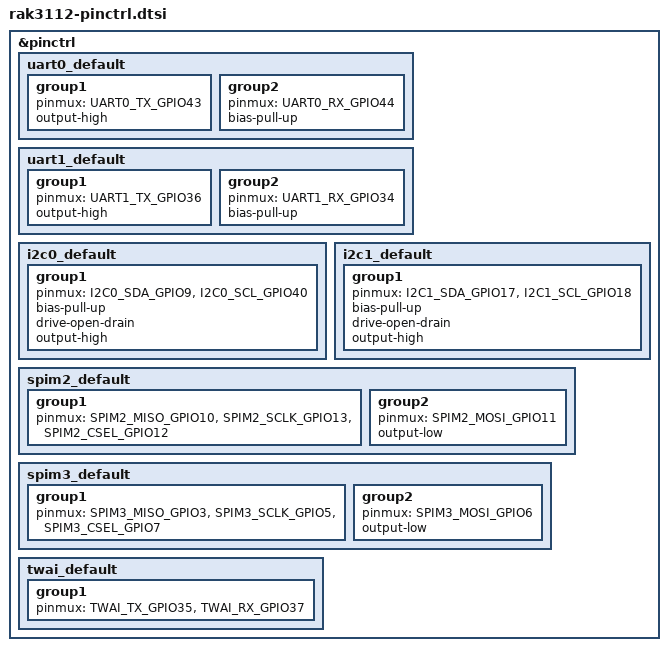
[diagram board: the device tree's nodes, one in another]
/*
 * Copyright (c) 2025 RAKwireless Technology Co., Ltd. <www.rakwireless.com>
 * Sercan Erat <sercanerat@gmail.com>
 * SPDX-License-Identifier: Apache-2.0
 */

/* Do not assign GPIO19 and GPIO20 to any peripheral.
 * These are USB pins.
 */

#include <dt-bindings/pinctrl/esp32s3-pinctrl.h>
#include <zephyr/dt-bindings/pinctrl/esp-pinctrl-common.h>
#include <zephyr/dt-bindings/pinctrl/esp32s3-gpio-sigmap.h>

&pinctrl {
	uart0_default: uart0_default {
		group1 {
			pinmux = <UART0_TX_GPIO43>;
			output-high;
		};
		group2 {
			pinmux = <UART0_RX_GPIO44>;
			bias-pull-up;
		};
	};

	uart1_default: uart1_default {
		/* Not available in the 8MB and 16MB PSRAM version */
		group1 {
			pinmux = <UART1_TX_GPIO36>;
			output-high;
		};
		group2 {
			pinmux = <UART1_RX_GPIO34>;
			bias-pull-up;
		};
	};

	i2c0_default: i2c0_default {
		group1 {
			pinmux = <I2C0_SDA_GPIO9>,
				 <I2C0_SCL_GPIO40>;
			bias-pull-up;
			drive-open-drain;
			output-high;
		};
	};

	i2c1_default: i2c1_default {
		group1 {
			pinmux = <I2C1_SDA_GPIO17>,
				 <I2C1_SCL_GPIO18>;
			bias-pull-up;
			drive-open-drain;
			output-high;
		};
	};

	spim2_default: spim2_default {
		group1 {
			pinmux = <SPIM2_MISO_GPIO10>,
				 <SPIM2_SCLK_GPIO13>,
				 <SPIM2_CSEL_GPIO12>;
		};
		group2 {
			pinmux = <SPIM2_MOSI_GPIO11>;
			output-low;
		};
	};

	spim3_default: spim3_default {
		group1 {
			pinmux = <SPIM3_MISO_GPIO3>,
				 <SPIM3_SCLK_GPIO5>,
				 <SPIM3_CSEL_GPIO7>;
		};
		group2 {
			pinmux = <SPIM3_MOSI_GPIO6>;
			output-low;
		};
	};

	twai_default: twai_default {
		/* Not available in the 8MB and 16MB PSRAM version */
		group1 {
			pinmux = <TWAI_TX_GPIO35>,
				<TWAI_RX_GPIO37>;
		};
	};
};
